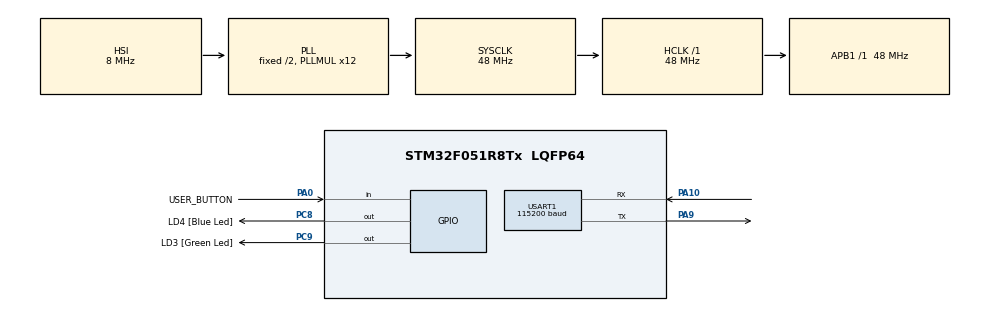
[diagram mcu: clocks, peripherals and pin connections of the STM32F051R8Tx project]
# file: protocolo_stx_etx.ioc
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CRC.InputDataFormat=CRC_INPUTDATA_FORMAT_WORDS
FREERTOS.Tasks01=defaultTask,0,128,StartDefaultTask,Default,NULL
FREERTOS.configGENERATE_RUN_TIME_STATS=0
FREERTOS.configTOTAL_HEAP_SIZE=5120
FREERTOS.configUSE_STATS_FORMATTING_FUNCTIONS=0
FREERTOS.configUSE_TRACE_FACILITY=1
Mcu.Family=STM32F0
Mcu.Name=STM32F051R8Tx
Mcu.Package=LQFP64
NVIC.USART1_IRQn=true\:3\:0\:false\:true\:true\:1\:true\:true\:true
PA0.GPIO_Label=USER_BUTTON
PA0.Signal=GPIO_Input
PA10.Mode=Asynchronous
PA10.Signal=USART1_RX
PA13.GPIO_Label=SWDIO
PA13.Mode=Serial_Wire
PA13.Signal=SYS_SWDIO
PA14.GPIO_Label=SWCLK
PA14.Mode=Serial_Wire
PA14.Signal=SYS_SWCLK
PA9.Mode=Asynchronous
PA9.Signal=USART1_TX
PC8.GPIO_Label=LD4 [Blue Led]
PC8.Signal=GPIO_Output
PC9.GPIO_Label=LD3 [Green Led]
PC9.Signal=GPIO_Output
ProjectManager.HeapSize=0x200
ProjectManager.StackSize=0x400
ProjectManager.TargetToolchain=Makefile
RCC.AHBFreq_Value=48000000
RCC.APB1Freq_Value=48000000
RCC.APB1TimFreq_Value=48000000
RCC.HCLKFreq_Value=48000000
RCC.PLLMUL=RCC_PLL_MUL12
RCC.SYSCLKFreq_VALUE=48000000
RCC.SYSCLKSource=RCC_SYSCLKSOURCE_PLLCLK
USART1.BaudRate=115200
USART1.VirtualMode-Asynchronous=VM_ASYNC
VP_CRC_VS_CRC.Mode=CRC_Activate
VP_FREERTOS_VS_CMSIS_V1.Mode=CMSIS_V1
board=STM32F0DISCOVERY

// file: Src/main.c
/* USER CODE BEGIN Header */
/**
  ******************************************************************************
  * @file           : main.c
  * @brief          : Main program body
  ******************************************************************************
  * @attention
  *
  * <h2><center>&copy; Copyright (c) 2019 STMicroelectronics.
  * All rights reserved.</center></h2>
  *
  * This software component is licensed by ST under Ultimate Liberty license
  * SLA0044, the "License"; You may not use this file except in compliance with
  * the License. You may obtain a copy of the License at:
  *                             www.st.com/SLA0044
  *
  ******************************************************************************
  */
/* USER CODE END Header */

#include "main.h"
#include "cmsis_os.h"
#include "crc.h"
#include "usart.h"
#include "gpio.h"

void SystemClock_Config(void);
void MX_FREERTOS_Init(void);
static void MX_NVIC_Init(void);

int main(void)
{

  /* MCU Configuration--------------------------------------------------------*/

  /* Reset of all peripherals, Initializes the Flash interface and the Systick. */
  HAL_Init();

  /* Configure the system clock */
  SystemClock_Config();

  /* Initialize all configured peripherals */
  MX_GPIO_Init();
  MX_USART1_UART_Init();
  MX_CRC_Init();

  /* Initialize interrupts */
  MX_NVIC_Init();
  /* USER CODE BEGIN 2 */
  MX_USART1_UART_EnableIRQ();
  /* USER CODE END 2 */

  /* Call init function for freertos objects (in freertos.c) */
  MX_FREERTOS_Init();

  /* Start scheduler */
  osKernelStart();

  /* We should never get here as control is now taken by the scheduler */

  /* Infinite loop */
  while (1)
  {

  }
}

void SystemClock_Config(void)
{
  RCC_OscInitTypeDef RCC_OscInitStruct = {0};
  RCC_ClkInitTypeDef RCC_ClkInitStruct = {0};
  RCC_PeriphCLKInitTypeDef PeriphClkInit = {0};

  /** Initializes the CPU, AHB and APB busses clocks
  */
  RCC_OscInitStruct.OscillatorType = RCC_OSCILLATORTYPE_HSI;
  RCC_OscInitStruct.HSIState = RCC_HSI_ON;
  RCC_OscInitStruct.HSICalibrationValue = RCC_HSICALIBRATION_DEFAULT;
  RCC_OscInitStruct.PLL.PLLState = RCC_PLL_ON;
  RCC_OscInitStruct.PLL.PLLSource = RCC_PLLSOURCE_HSI;
  RCC_OscInitStruct.PLL.PLLMUL = RCC_PLL_MUL12;
  RCC_OscInitStruct.PLL.PREDIV = RCC_PREDIV_DIV1;
  if (HAL_RCC_OscConfig(&RCC_OscInitStruct) != HAL_OK)
  {
    Error_Handler();
  }
  /** Initializes the CPU, AHB and APB busses clocks
  */
  RCC_ClkInitStruct.ClockType = RCC_CLOCKTYPE_HCLK|RCC_CLOCKTYPE_SYSCLK
                              |RCC_CLOCKTYPE_PCLK1;
  RCC_ClkInitStruct.SYSCLKSource = RCC_SYSCLKSOURCE_PLLCLK;
  RCC_ClkInitStruct.AHBCLKDivider = RCC_SYSCLK_DIV1;
  RCC_ClkInitStruct.APB1CLKDivider = RCC_HCLK_DIV1;

  if (HAL_RCC_ClockConfig(&RCC_ClkInitStruct, FLASH_LATENCY_1) != HAL_OK)
  {
    Error_Handler();
  }
  PeriphClkInit.PeriphClockSelection = RCC_PERIPHCLK_USART1;
  PeriphClkInit.Usart1ClockSelection = RCC_USART1CLKSOURCE_PCLK1;
  if (HAL_RCCEx_PeriphCLKConfig(&PeriphClkInit) != HAL_OK)
  {
    Error_Handler();
  }
}

/**
  * @brief NVIC Configuration.
  * @retval None
  */
static void MX_NVIC_Init(void)
{
  /* USART1_IRQn interrupt configuration */
  HAL_NVIC_SetPriority(USART1_IRQn, 3, 0);
  HAL_NVIC_EnableIRQ(USART1_IRQn);
}

void Error_Handler(void)
{
}

/************************ (C) COPYRIGHT STMicroelectronics *****END OF FILE****/

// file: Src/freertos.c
/* USER CODE BEGIN Header */
/**
  ******************************************************************************
  * File Name          : freertos.c
  * Description        : Code for freertos applications
  ******************************************************************************
  * @attention
  *
  * <h2><center>&copy; Copyright (c) 2019 STMicroelectronics.
  * All rights reserved.</center></h2>
  *
  * This software component is licensed by ST under Ultimate Liberty license
  * SLA0044, the "License"; You may not use this file except in compliance with
  * the License. You may obtain a copy of the License at:
  *                             www.st.com/SLA0044
  *
  ******************************************************************************
  */
/* USER CODE END Header */

#include "FreeRTOS.h"
#include "task.h"
#include "main.h"
#include "cmsis_os.h"

/* USER CODE BEGIN Includes */
#include "../Inc/stx_etx.h"
#include "../Inc/app.h"

/* USER CODE END Includes */

/* USER CODE BEGIN Variables */
//extern UART_HandleTypeDef huart1;
/* USER CODE END Variables */
osThreadId defaultTaskHandle;

void StartDefaultTask(void const * argument);

void MX_FREERTOS_Init(void); /* (MISRA C 2004 rule 8.1) */

void MX_FREERTOS_Init(void) {

  /* Create the thread(s) */
  /* definition and creation of defaultTask */
  osThreadDef(defaultTask, StartDefaultTask, osPriorityNormal, 0, 128);
  defaultTaskHandle = osThreadCreate(osThread(defaultTask), NULL);

}

void StartDefaultTask(void const * argument)
{

  /* USER CODE BEGIN StartDefaultTask */
	/* Infinite loop */
	stx_etx_init();
	app_init();

	for(;;)
	{
		//osDelay(1000);
		osThreadTerminate(defaultTaskHandle);
	}
  /* USER CODE END StartDefaultTask */
}

/************************ (C) COPYRIGHT STMicroelectronics *****END OF FILE****/
